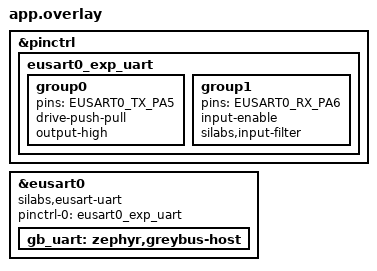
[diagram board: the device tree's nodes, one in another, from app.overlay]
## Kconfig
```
# Copyright (c) 2025 Ayush Singh, BeagleBoard.org
#
# SPDX-License-Identifier: Apache-2.0

mainmenu "Greybus basic sample"

config PRINT_MANIFEST
	bool "Print greybus manifest fetched from device at startup"
	depends on GREYBUS
	help
	  Print greybus manifest at application startup

source "Kconfig.zephyr"
```

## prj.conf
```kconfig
# Copyright (c) 2025 Ayush Singh, BeagleBoard.org
#
# SPDX-License-Identifier: Apache-2.0

CONFIG_GREYBUS=y
CONFIG_GREYBUS_NODE=n
CONFIG_GREYBUS_HOST=y

CONFIG_SERIAL=y
CONFIG_GREYBUS_XPORT_UART_HDLC=y

CONFIG_LOG=y
CONFIG_GREYBUS_LOG_LEVEL_DBG=y

CONFIG_GPIO=y
CONFIG_GPIO_GET_DIRECTION=y
CONFIG_GREYBUS_GPIO=y
```

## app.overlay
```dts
/*
 * Copyright (c) 2025 Ayush Singh, BeagleBoard.org
 *
 * SPDX-License-Identifier: Apache-2.0
 */

/ {

};

&pinctrl {
	eusart0_exp_uart: eusart0_exp_uart {
		group0 {
			pins = <EUSART0_TX_PA5>;
			drive-push-pull;
			output-high;
		};

		group1 {
			pins = <EUSART0_RX_PA6>;
			input-enable;
			silabs,input-filter;
		};
	};
};

&eusart0 {
	compatible = "silabs,eusart-uart";
	pinctrl-0 = <&eusart0_exp_uart>;
	pinctrl-names = "default";
	status = "okay";

	gb_uart: zephyr,greybus-host {
		status = "okay";
	};
};
```

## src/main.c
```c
/*
 * Copyright (c) 2016 Open-RnD Sp. z o.o.
 * Copyright (c) 2020 Nordic Semiconductor ASA
 *
 * SPDX-License-Identifier: Apache-2.0
 *
 * NOTE: If you are looking into an implementation of button events with
 * debouncing, check out `input` subsystem and `samples/subsys/input/input_dump`
 * example instead.
 */

#include <zephyr/kernel.h>
#include <zephyr/device.h>
#include <zephyr/drivers/gpio.h>
#include <zephyr/sys/util.h>
#include <zephyr/sys/printk.h>
#include <inttypes.h>

#define SLEEP_TIME_MS 1

/*
 * Get button configuration from the devicetree sw0 alias. This is mandatory.
 */
#define SW0_NODE DT_ALIAS(sw0)
#if !DT_NODE_HAS_STATUS_OKAY(SW0_NODE)
#error "Unsupported board: sw0 devicetree alias is not defined"
#endif
static const struct gpio_dt_spec button = GPIO_DT_SPEC_GET_OR(SW0_NODE, gpios, {0});
static struct gpio_callback button_cb_data;

/*
 * The led0 devicetree alias is optional. If present, we'll use it
 * to turn on the LED whenever the button is pressed.
 */
static const struct device *led;
static bool toggle_led = false;
static bool led_state = false;

void button_pressed(const struct device *dev, struct gpio_callback *cb, uint32_t pins)
{
	printk("Button pressed at %" PRIu32 "\n", k_cycle_get_32());

	toggle_led = true;
}

int main(void)
{
	int ret;

	if (!gpio_is_ready_dt(&button)) {
		printk("Error: button device %s is not ready\n", button.port->name);
		return 0;
	}

	ret = gpio_pin_configure_dt(&button, GPIO_INPUT);
	if (ret != 0) {
		printk("Error %d: failed to configure %s pin %d\n", ret, button.port->name,
		       button.pin);
		return 0;
	}

	ret = gpio_pin_interrupt_configure_dt(&button, GPIO_INT_EDGE_TO_ACTIVE);
	if (ret != 0) {
		printk("Error %d: failed to configure interrupt on %s pin %d\n", ret,
		       button.port->name, button.pin);
		return 0;
	}

	gpio_init_callback(&button_cb_data, button_pressed, BIT(button.pin));
	gpio_add_callback(button.port, &button_cb_data);
	printk("Set up button at %s pin %d\n", button.port->name, button.pin);

	while (1) {
		led = device_get_binding("gpio_greybush_0");
		if (led) {
			break;
		}

		k_msleep(100);
	}

	ret = gpio_pin_configure(led, 2, GPIO_OUTPUT);
	if (ret != 0) {
		printk("Error %d: failed to configure LED device %s pin %d\n", ret, led->name, 0);
		led = NULL;
	} else {
		printk("Set up LED at %s pin %d\n", led->name, 2);
	}

	printk("Press the button\n");

	while (1) {
		if (toggle_led) {
			led_state = !led_state;
			gpio_pin_set(led, 2, led_state);
			toggle_led = false;
		}
		k_msleep(100);
	}
	return 0;
}
```
